AUTOSAR XML (schema 00046)
package /ComponentTypes
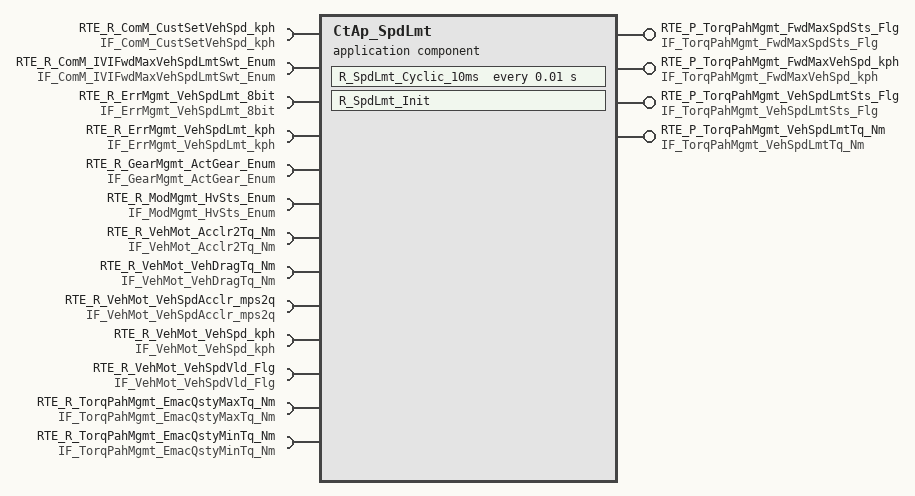
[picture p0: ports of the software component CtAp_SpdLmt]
  application sw component type CtAp_SpdLmt
    9 x require port:
      RTE_R_ComM_CustSetVehSpd_kph: nonqueued-receiver-com-spec{data-element=tec_ComM_IVISetFwdVehSpd_kph, filter=data-filter-type=ALWAYS, init-value=0}, required-interface=IF_ComM_CustSetVehSpd_kph
      RTE_R_ComM_IVIFwdMaxVehSpdLmtSwt_Enum: nonqueued-receiver-com-spec{data-element=tec_ComM_IVIFwdMaxVehSpdLmtSwt_Enum, filter=data-filter-type=ALWAYS, init-value=0}, required-interface=IF_ComM_IVIFwdMaxVehSpdLmtSwt_Enum
      RTE_R_ErrMgmt_VehSpdLmt_8bit: nonqueued-receiver-com-spec{data-element=tec_ErrMgmt_VehSpdLmt_8bit, filter=data-filter-type=ALWAYS, init-value=0}, required-interface=IF_ErrMgmt_VehSpdLmt_8bit
      RTE_R_ErrMgmt_VehSpdLmt_kph: nonqueued-receiver-com-spec{data-element=tec_ErrMgmt_VehSpdLmt_kph, filter=data-filter-type=ALWAYS, init-value=0}, required-interface=IF_ErrMgmt_VehSpdLmt_kph
      RTE_R_GearMgmt_ActGear_Enum: nonqueued-receiver-com-spec{data-element=tec_GearMgmt_ActGear_Enum, filter=data-filter-type=ALWAYS, init-value=0}, required-interface=IF_GearMgmt_ActGear_Enum
      RTE_R_ModMgmt_HvSts_Enum: nonqueued-receiver-com-spec{data-element=tec_ModMgmt_HvSts_Enum, filter=data-filter-type=ALWAYS, init-value=0}, required-interface=IF_ModMgmt_HvSts_Enum
      RTE_R_VehMot_Acclr2Tq_Nm: nonqueued-receiver-com-spec{data-element=tec_VehMot_Acclr2Tq_Nm, filter=data-filter-type=ALWAYS, init-value=0}, required-interface=IF_VehMot_Acclr2Tq_Nm
      RTE_R_VehMot_VehDragTq_Nm: nonqueued-receiver-com-spec{data-element=tec_VehMot_VehDragTq_Nm, filter=data-filter-type=ALWAYS, init-value=0}, required-interface=IF_VehMot_VehDragTq_Nm
      RTE_R_VehMot_VehSpdAcclr_mps2q: nonqueued-receiver-com-spec{data-element=tec_VehMot_VehSpdAcclr_mps2q, filter=data-filter-type=ALWAYS, init-value=0}, required-interface=IF_VehMot_VehSpdAcclr_mps2q
    4 x provide port:
      RTE_P_TorqPahMgmt_FwdMaxSpdSts_Flg: nonqueued-sender-com-spec{data-element=tec_TorqPahMgmt_FwdMaxSpdSts_Flg, init-value=0}, provided-interface=IF_TorqPahMgmt_FwdMaxSpdSts_Flg
      RTE_P_TorqPahMgmt_FwdMaxVehSpd_kph: nonqueued-sender-com-spec{data-element=tec_TorqPahMgmt_FwdMaxVehSpd_kph, init-value=0}, provided-interface=IF_TorqPahMgmt_FwdMaxVehSpd_kph
      RTE_P_TorqPahMgmt_VehSpdLmtSts_Flg: nonqueued-sender-com-spec{data-element=tec_TorqPahMgmt_VehSpdLmtSts_Flg, init-value=0}, provided-interface=IF_TorqPahMgmt_VehSpdLmtSts_Flg
      RTE_P_TorqPahMgmt_VehSpdLmtTq_Nm: nonqueued-sender-com-spec{data-element=tec_TorqPahMgmt_VehSpdLmtTq_Nm, init-value=0}, provided-interface=IF_TorqPahMgmt_VehSpdLmtTq_Nm
    4 x require port:
      RTE_R_VehMot_VehSpd_kph: nonqueued-receiver-com-spec{data-element=tec_VehMot_VehSpd_kph, filter=data-filter-type=ALWAYS, init-value=0}, required-interface=IF_VehMot_VehSpd_kph
      RTE_R_VehMot_VehSpdVld_Flg: nonqueued-receiver-com-spec{data-element=tec_VehMot_VehSpdVld_Flg, filter=data-filter-type=ALWAYS, init-value=0}, required-interface=IF_VehMot_VehSpdVld_Flg
      RTE_R_TorqPahMgmt_EmacQstyMaxTq_Nm: nonqueued-receiver-com-spec{data-element=tec_TorqPahMgmt_EmacQstyMaxTq_Nm, filter=data-filter-type=ALWAYS, init-value=0}, required-interface=IF_TorqPahMgmt_EmacQstyMaxTq_Nm
      RTE_R_TorqPahMgmt_EmacQstyMinTq_Nm: nonqueued-receiver-com-spec{data-element=tec_TorqPahMgmt_EmacQstyMinTq_Nm, filter=data-filter-type=ALWAYS, init-value=0}, required-interface=IF_TorqPahMgmt_EmacQstyMinTq_Nm
    behavior CtAp_SpdLmt_InternalBehavior
      init event CtAp_TorqLmt_InitEvent: start-on-event=R_SpdLmt_Init
      timing event TMT_R_SpdLmt_Cyclic_10ms: start-on-event=R_SpdLmt_Cyclic_10ms, period=0.01
      runnable R_SpdLmt_Init
      runnable R_SpdLmt_Cyclic_10ms
        data-receive-point-by-arguments:
          13 x access:
            REC_RTE_R_ComM_CustSetVehSpd_kph_tec_ComM_IVISetFwdVehSpd_kph: accessed-variable=RTE_R_ComM_CustSetVehSpd_kph.tec_ComM_IVISetFwdVehSpd_kph
            REC_RTE_R_ComM_IVIFwdMaxVehSpdLmtSwt_Enum_tec_ComM_IVIFwdMaxVehSpdLmtSwt_Enum: accessed-variable=RTE_R_ComM_IVIFwdMaxVehSpdLmtSwt_Enum.tec_ComM_IVIFwdMaxVehSpdLmtSwt_Enum
            REC_RTE_R_ErrMgmt_VehSpdLmt_8bit_tec_ErrMgmt_VehSpdLmt_8bit: accessed-variable=RTE_R_ErrMgmt_VehSpdLmt_8bit.tec_ErrMgmt_VehSpdLmt_8bit
            REC_RTE_R_ErrMgmt_VehSpdLmt_kph_tec_ErrMgmt_VehSpdLmt_kph: accessed-variable=RTE_R_ErrMgmt_VehSpdLmt_kph.tec_ErrMgmt_VehSpdLmt_kph
            REC_RTE_R_GearMgmt_ActGear_Enum_tec_GearMgmt_ActGear_Enum: accessed-variable=RTE_R_GearMgmt_ActGear_Enum.tec_GearMgmt_ActGear_Enum
            REC_RTE_R_ModMgmt_HvSts_Enum_tec_ModMgmt_HvSts_Enum: accessed-variable=RTE_R_ModMgmt_HvSts_Enum.tec_ModMgmt_HvSts_Enum
            REC_RTE_R_VehMot_Acclr2Tq_Nm_tec_VehMot_Acclr2Tq_Nm: accessed-variable=RTE_R_VehMot_Acclr2Tq_Nm.tec_VehMot_Acclr2Tq_Nm
            REC_RTE_R_VehMot_VehDragTq_Nm_tec_VehMot_VehDragTq_Nm: accessed-variable=RTE_R_VehMot_VehDragTq_Nm.tec_VehMot_VehDragTq_Nm
            REC_RTE_R_VehMot_VehSpdAcclr_mps2q_tec_VehMot_VehSpdAcclr_mps2q: accessed-variable=RTE_R_VehMot_VehSpdAcclr_mps2q.tec_VehMot_VehSpdAcclr_mps2q
            SEND_RTE_P_TorqPahMgmt_EmacQstyMinTq_Nm_tec_TorqPahMgmt_EmacQstyMinTq_Nm: accessed-variable=RTE_R_TorqPahMgmt_EmacQstyMinTq_Nm.tec_TorqPahMgmt_EmacQstyMinTq_Nm
            SEND_RTE_P_TorqPahMgmt_EmacQstyMaxTq_Nm_tec_TorqPahMgmt_EmacQstyMaxTq_Nm: accessed-variable=RTE_R_TorqPahMgmt_EmacQstyMaxTq_Nm.tec_TorqPahMgmt_EmacQstyMaxTq_Nm
            REC_RTE_R_VehMot_VehSpdVld_Flg_tec_VehMot_VehSpdVld_Flg: accessed-variable=RTE_R_VehMot_VehSpdVld_Flg.tec_VehMot_VehSpdVld_Flg
            REC_RTE_R_VehMot_VehSpd_kph_tec_VehMot_VehSpd_kph: accessed-variable=RTE_R_VehMot_VehSpd_kph.tec_VehMot_VehSpd_kph
        data-send-points:
          4 x access:
            SEND_RTE_P_TorqPahMgmt_FwdMaxSpdSts_Flg_tec_TorqPahMgmt_FwdMaxSpdSts_Flg: accessed-variable=RTE_P_TorqPahMgmt_FwdMaxSpdSts_Flg.tec_TorqPahMgmt_FwdMaxSpdSts_Flg
            SEND_RTE_P_TorqPahMgmt_FwdMaxVehSpd_kph_tec_TorqPahMgmt_FwdMaxVehSpd_kph: accessed-variable=RTE_P_TorqPahMgmt_FwdMaxVehSpd_kph.tec_TorqPahMgmt_FwdMaxVehSpd_kph
            SEND_RTE_P_TorqPahMgmt_VehSpdLmtSts_Flg_tec_TorqPahMgmt_VehSpdLmtSts_Flg: accessed-variable=RTE_P_TorqPahMgmt_VehSpdLmtSts_Flg.tec_TorqPahMgmt_VehSpdLmtSts_Flg
            SEND_RTE_P_TorqPahMgmt_VehSpdLmtTq_Nm_tec_TorqPahMgmt_VehSpdLmtTq_Nm: accessed-variable=RTE_P_TorqPahMgmt_VehSpdLmtTq_Nm.tec_TorqPahMgmt_VehSpdLmtTq_Nm
  swc implementation CtAp_SpdLmt_Implementation: behavior=CtAp_SpdLmt_InternalBehavior
    code-descriptors:
      code Default: artifact-descriptors=autosar-engineering-object={short-label=Default, category=SWOBJ}
